# NUC123AN_v1 register map
File version: 1.0
Registers are 32-bit, read-write, reset 0x0 unless marked. A register's access mark holds for its fields unless they carry their own. Offsets are from the block's base; [hi:lo] are bit positions; {n}, {i} and the like mark numbered series; 'fields as' and 'values as' point back to an identical list.

## I2C0 — I2C Register Map
Base 0x40020000
Same registers: I2C1 0x40120000
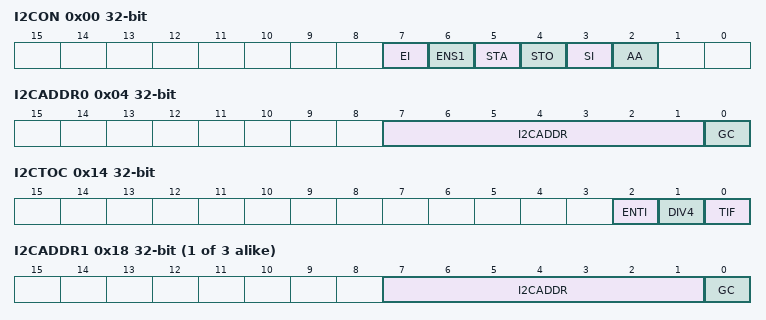
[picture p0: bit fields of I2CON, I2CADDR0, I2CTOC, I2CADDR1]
0x00 I2CON — I2C Control Register
  [7] EI — Enable Interrupt
    0=I2C interrupt Disabled; 1=I2C interrupt Enabled
  [6] ENS1 — I2C Controller Enable Bit
    0=Disabled; 1=Enabled
  [5] STA — I2C START Control Bit. Setting STA to logic 1 to enter Master mode, the I2C hardware sends a START or repeat START condition to bus when the bus is free.
  [4] STO — I2C STOP Control Bit. In Master mode, setting STO to transmit a STOP condition to bus then I2C hardware will check the bus condition if a STOP condition is detected this bit will be cleared by hardware automatically. In a Slave mode, setting STO resets I2C hardware to the defined "not addressed" Slave mode. This means it is NO LONGER in the slave receiver mode to receive data from the master transmit device.
  [3] SI — I2C Interrupt Flag. When a new I2C state is present in the I2CSTATUS register, the SI flag is set by hardware, and if bit EI (I2CON [7]) is set, the I2C interrupt is requested. SI must be cleared by software. Clear SI is by writing 1 to this bit.
  [2] AA — Assert Acknowledge Control Bit
0x04 I2CADDR0 — I2C Slave Address Register0
  [7:1] I2CADDR — I2C Address Register. The content of this register is irrelevant when I2C is in Master mode. In Slave mode, the seven most significant bits must be loaded with the chip's own address. The I2C hardware will react if either of the addresses is matched.
  [0] GC — General Call Function
    0=General Call function Disabled; 1=General Call function Enabled
0x08 I2CDAT — I2C Data Register
  [7:0] I2CDAT — I2C Data Register. Bit [7:0] is located with the 8-bit transferred data of I2C serial port.
0x0C I2CSTATUS ro reset 0xF8
  [7:0] I2CSTATUS — I2C Status Register. The status register of I2C:
0x10 I2CLK — I2C Clock Divided Register
  [7:0] I2CLK — I2C clock divided Register
0x14 I2CTOC — I2C Time-Out Counter Register
  [2] ENTI — Time-out Counter Enable/Disable. When Enabled, the 14-bit time-out counter will start counting when SI is cleared. Setting the flag SI to high will reset counter and re-start counting up after SI is cleared.
    0=Disabled; 1=Enabled
  [1] DIV4 — Time-out Counter Input Clock Divided by 4. When Enabled, the time-out period is extend 4 times.
    0=Disabled; 1=Enabled
  [0] TIF — Time-Out Flag
    0=Software can clear the flag; 1=Time-out flag is set by H/W. It can interrupt CPU
{0x14+4i} I2CADDR{i} (i=1..3) — I2C Slave Address Register{i}
  fields as I2CADDR0
{0x24+4i} I2CADM{i} (i=0..3) — I2C Slave Address Mask Register{i}
  [7:1] I2CADM — I2C Address Mask Register. I2C bus controllers support multiple address recognition with four address mask register. When the bit in the address mask register is set to one, it means the received corresponding address bit is don't-care. If the bit is set to zero, it means the received corresponding register bit should be exact the same as address register.
    0=Mask Disabled (the received corresponding register bit should be exactly the same as address register.); 1=Mask Enabled (the received corresponding address bit is don't care.)
0x3C I2CWKUPCON — I2C Wake-up Control Register
  [0] WKUPEN — I2C Wake-up Function Enable
    0=I2C wake-up function Disabled; 1=I2C wake-up function Enabled
0x40 I2CWKUPSTS ro — I2C Wake-up Status Register
  [0] WKUPIF — Wake-up Interrupt Flag. Software can write one to clear this flag
    0=Wake-up flag inactive; 1=Wake-up flag active

## WDT — WDT Register Map
Base 0x40004000
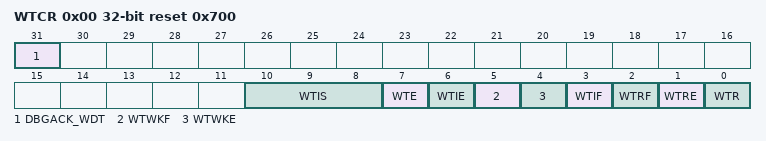
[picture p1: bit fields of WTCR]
0x00 WTCR reset 0x700 — Watchdog Timer Control Register
  [31] DBGACK_WDT — ICE Debug Mode Acknowledge Disable (Write-protection Bit). Watchdog Timer counter will keep going no matter ICE debug mode acknowledged or not.
    0=ICE debug mode acknowledgement affects Watchdog Timer counting; 1=ICE debug mode acknowledgement Disabled
  [10:8] WTIS — Watchdog Timer Interval Selection (Write-protection Bit)
  [7] WTE — Watchdog Timer Enable (Write-protection Bit)
    0=Watchdog timer Disabled (This action will reset the internal counter); 1=Watchdog timer Enabled
  [6] WTIE — Watchdog Timer Interrupt Enable (Write-protection Bit)
    0=Watchdog timer interrupt Disabled; 1=Watchdog timer interrupt Enabled
  [5] WTWKF — Watchdog Timer Wake-up Flag. If Watchdog timer causes chip to wake up from Power-down mode, this bit will be set to high. It must be cleared by software by writing 1 to this bit.
    0=Watchdog timer does not cause chip wake up; 1=Chip woken up from Idle or Power-down mode by Watchdog time-out
  [4] WTWKE — Watchdog Timer Wake-up Function Enable bit (Write-protection Bit). Note: Chip can be woken up by WDT only if WDT clock source select RC10K.
    0=Watchdog timer Wake-up chip function Disabled; 1=Wake-up function Enabled so that Watchdog timer time-out can wake-up chip from Power-down mode
  [3] WTIF — Watchdog Timer Interrupt Flag. If the Watchdog timer interrupt is enabled, the hardware will set this bit to indicate that the Watchdog timer interrupt has occurred. Note: This bit is cleared by writing 1 to this bit.
    0=Watchdog timer interrupt did not occur; 1=Watchdog timer interrupt occurred
  [2] WTRF — Watchdog Timer Reset Flag. When the Watchdog timer initiates a reset, the hardware will set this bit. This flag can be read by software to determine the source of reset. Software is responsible to clear it manually by writing 1 to it. If WTRE is disabled, the Watchdog timer has no effect on this bit. Note: This bit is cleared by writing 1 to this bit.
    0=Watchdog timer reset did not occur; 1=Watchdog timer reset occurred
  [1] WTRE — Watchdog Timer Reset Enable (Write-protection Bit). Setting this bit will enable the Watchdog timer reset function.
    0=Watchdog timer reset function Disabled; 1=Watchdog timer reset function Enabled
  [0] WTR — Clear Watchdog Timer (Write-protection Bit). Setting this bit will clear the Watchdog timer. Note: This bit will be automatically cleared by hardware.
    0=No effect; 1=Reset the contents of the Watchdog timer
0x04 WTCRALT — Watchdog Timer Alternative Control Register
  [1:0] WTRDSEL — Watchdog Timer Reset Delay Select (Write-protection Bits). When watchdog time-out happened, software has a time named watchdog reset delay period to clear watchdog timer to prevent watchdog reset happened. Software can select a suitable value of watchdog reset delay period for different watchdog time-out period. These bits are protected bit. It means programming this bit needs to write "59h", "16h", "88h" to address 0x5000_0100 to disable register protection. Reference the register REGWRPROT at address GCR_BA+0x100. This register will be reset if watchdog reset happened
    0=Watchdog reset delay period is 1024 watchdog clock; 1=Watchdog reset delay period is 128 watchdog clock; 2=Watchdog reset delay period is 16 watchdog clock; 3=Watchdog reset delay period is 1 watchdog clock

## WWDT — WWDT Register Map
Base 0x40004100
0x00 WWDTRLD wo — Window Watchdog Timer Reload Counter Register
  [31:0] WWDTRLD — WWDT Reload Counter Register. Writing 0x00005AA5 to this register will reload the Window Watchdog Timer counter value to 0x3F. Note: Software can only write WWDTRLD when WWDT counter value between 0 and WINCMP. If software writes WWDTRLD when WWDT counter value larger than WINCMP, WWDT will generate RESET signal.
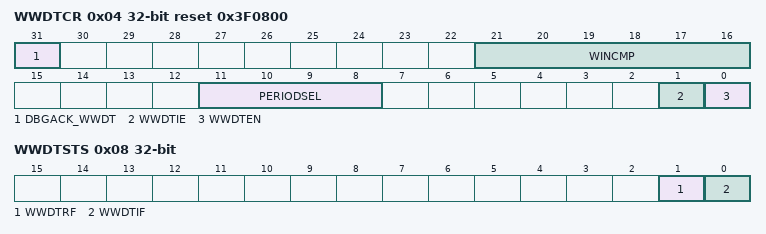
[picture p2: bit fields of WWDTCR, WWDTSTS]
0x04 WWDTCR reset 0x3F0800 — Window Watchdog Timer Control Register
  [31] DBGACK_WWDT — ICE debug mode acknowledge Disable
    0=WWDT count stopped if system is in Debug mode; 1=WWDT still count even system is in Debug mode
  [21:16] WINCMP — WWDT Window Compare Register. Set this register to adjust the valid reload window. Note: Software can only write WWDTRLD when WWDT counter value between 0 and WINCMP. If software writes WWDTRLD when WWDT counter value is larger than WWCMP, WWDT will generate RESET signal.
  [11:8] PERIODSEL — WWDT Pre-scale Period Select
  [1] WWDTIE — WWDT Interrupt Enable. Set this bit to enable the Watchdog timer interrupt function.
    0=Watchdog timer interrupt function Disabled; 1=Watchdog timer interrupt function Enabled
  [0] WWDTEN — WWDT Enable. Set this bit to enable the Window Watchdog timer.
    0=Window Watchdog timer function Disabled; 1=Window Watchdog timer function Enabled
0x08 WWDTSTS — Window Watchdog Timer Status Register
  [1] WWDTRF — WWDT Reset Flag. When WWDT counter counts down to 0 or writes WWDTRLD during WWDT counter larger than WINCMP, chip will be reset and this bit is set to 1. Software can write 1 to clear this bit to 0.
  [0] WWDTIF — WWDT Compare Match Interrupt Flag. When WWCMP matches the WWDT counter, this bit is set to 1. This bit will be cleared by software write 1 to this bit.
0x0C WWDTCVR ro reset 0x3F — Window Watchdog Counter Value Register
  [5:0] WWDTCVAL — WWDT Counter Value. This register reflects the counter value of window watchdog. This register is read only.
